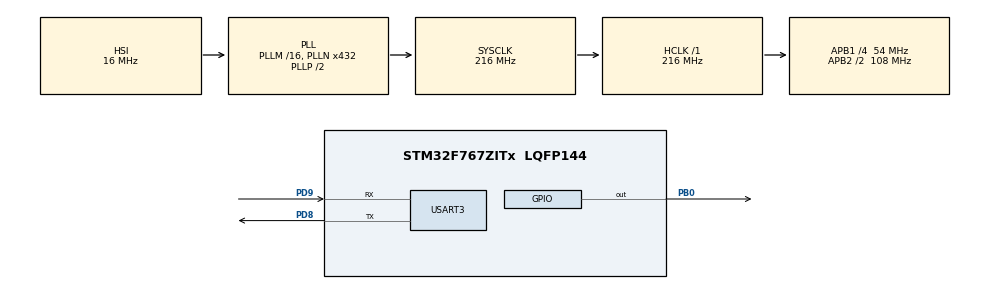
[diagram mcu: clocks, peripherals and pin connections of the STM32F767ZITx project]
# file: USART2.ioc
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Mcu.Family=STM32F7
Mcu.Name=STM32F767ZITx
Mcu.Package=LQFP144
NVIC.PriorityGroup=NVIC_PRIORITYGROUP_4
NVIC.USART3_IRQn=true\:0\:0\:false\:false\:true\:true\:true
PA13.Mode=Serial_Wire
PA13.Signal=SYS_JTMS-SWDIO
PA14.Mode=Serial_Wire
PA14.Signal=SYS_JTCK-SWCLK
PB0.Signal=GPIO_Output
PD8.Mode=Asynchronous
PD8.Signal=USART3_TX
PD9.Mode=Asynchronous
PD9.Signal=USART3_RX
ProjectManager.HeapSize=0x200
ProjectManager.StackSize=0x400
ProjectManager.TargetToolchain=STM32CubeIDE
RCC.AHBFreq_Value=216000000
RCC.APB1CLKDivider=RCC_HCLK_DIV4
RCC.APB1Freq_Value=54000000
RCC.APB1TimFreq_Value=108000000
RCC.APB2CLKDivider=RCC_HCLK_DIV2
RCC.APB2Freq_Value=108000000
RCC.APB2TimFreq_Value=216000000
RCC.CortexFreq_Value=216000000
RCC.HCLKFreq_Value=216000000
RCC.HSE_VALUE=25000000
RCC.HSI_VALUE=16000000
RCC.LSE_VALUE=32768
RCC.PLLN=432
RCC.SYSCLKFreq_VALUE=216000000
RCC.SYSCLKSource=RCC_SYSCLKSOURCE_PLLCLK
RCC.USBFreq_Value=216000000
RCC.VCOOutputFreq_Value=432000000
USART3.VirtualMode-Asynchronous=VM_ASYNC
board=custom

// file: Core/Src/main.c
/* USER CODE BEGIN Header */
/**
  ******************************************************************************
  * @file           : main.c
  * @brief          : Main program body
  ******************************************************************************
  * @attention
  *
  * Copyright (c) 2022 STMicroelectronics.
  * All rights reserved.
  *
  * This software is licensed under terms that can be found in the LICENSE file
  * in the root directory of this software component.
  * If no LICENSE file comes with this software, it is provided AS-IS.
  *
  ******************************************************************************
  */
/* USER CODE END Header */
#include "main.h"

/* USER CODE BEGIN Includes */
#include <stdio.h>
#include <string.h>

/* USER CODE END Includes */

UART_HandleTypeDef huart3;

void SystemClock_Config(void);
static void MX_GPIO_Init(void);
static void MX_USART3_UART_Init(void);

/* USER CODE BEGIN 0 */
char RX_data[5];
char RX_data_buffer[4];
/* USER CODE END 0 */

int main(void)
{

  /* MCU Configuration--------------------------------------------------------*/

  /* Reset of all peripherals, Initializes the Flash interface and the Systick. */
  HAL_Init();

  /* Configure the system clock */
  SystemClock_Config();

  /* Initialize all configured peripherals */
  MX_GPIO_Init();
  MX_USART3_UART_Init();
  HAL_UART_Receive_IT(&huart3, RX_data, 5);
  /* Infinite loop */
  while (1)
  {

  }
}

void SystemClock_Config(void)
{
  RCC_OscInitTypeDef RCC_OscInitStruct = {0};
  RCC_ClkInitTypeDef RCC_ClkInitStruct = {0};

  /** Configure the main internal regulator output voltage
  */
  __HAL_RCC_PWR_CLK_ENABLE();
  __HAL_PWR_VOLTAGESCALING_CONFIG(PWR_REGULATOR_VOLTAGE_SCALE1);
  /** Initializes the RCC Oscillators according to the specified parameters
  * in the RCC_OscInitTypeDef structure.
  */
  RCC_OscInitStruct.OscillatorType = RCC_OSCILLATORTYPE_HSI;
  RCC_OscInitStruct.HSIState = RCC_HSI_ON;
  RCC_OscInitStruct.HSICalibrationValue = RCC_HSICALIBRATION_DEFAULT;
  RCC_OscInitStruct.PLL.PLLState = RCC_PLL_ON;
  RCC_OscInitStruct.PLL.PLLSource = RCC_PLLSOURCE_HSI;
  RCC_OscInitStruct.PLL.PLLM = 16;
  RCC_OscInitStruct.PLL.PLLN = 432;
  RCC_OscInitStruct.PLL.PLLP = RCC_PLLP_DIV2;
  RCC_OscInitStruct.PLL.PLLQ = 2;
  RCC_OscInitStruct.PLL.PLLR = 2;
  if (HAL_RCC_OscConfig(&RCC_OscInitStruct) != HAL_OK)
  {
    Error_Handler();
  }
  /** Activate the Over-Drive mode
  */
  if (HAL_PWREx_EnableOverDrive() != HAL_OK)
  {
    Error_Handler();
  }
  /** Initializes the CPU, AHB and APB buses clocks
  */
  RCC_ClkInitStruct.ClockType = RCC_CLOCKTYPE_HCLK|RCC_CLOCKTYPE_SYSCLK
                              |RCC_CLOCKTYPE_PCLK1|RCC_CLOCKTYPE_PCLK2;
  RCC_ClkInitStruct.SYSCLKSource = RCC_SYSCLKSOURCE_PLLCLK;
  RCC_ClkInitStruct.AHBCLKDivider = RCC_SYSCLK_DIV1;
  RCC_ClkInitStruct.APB1CLKDivider = RCC_HCLK_DIV4;
  RCC_ClkInitStruct.APB2CLKDivider = RCC_HCLK_DIV2;

  if (HAL_RCC_ClockConfig(&RCC_ClkInitStruct, FLASH_LATENCY_7) != HAL_OK)
  {
    Error_Handler();
  }
}

static void MX_USART3_UART_Init(void)
{

  huart3.Instance = USART3;
  huart3.Init.BaudRate = 115200;
  huart3.Init.WordLength = UART_WORDLENGTH_8B;
  huart3.Init.StopBits = UART_STOPBITS_1;
  huart3.Init.Parity = UART_PARITY_NONE;
  huart3.Init.Mode = UART_MODE_TX_RX;
  huart3.Init.HwFlowCtl = UART_HWCONTROL_NONE;
  huart3.Init.OverSampling = UART_OVERSAMPLING_16;
  huart3.Init.OneBitSampling = UART_ONE_BIT_SAMPLE_DISABLE;
  huart3.AdvancedInit.AdvFeatureInit = UART_ADVFEATURE_NO_INIT;
  if (HAL_UART_Init(&huart3) != HAL_OK)
  {
    Error_Handler();
  }

}

static void MX_GPIO_Init(void)
{
  GPIO_InitTypeDef GPIO_InitStruct = {0};

  /* GPIO Ports Clock Enable */
  __HAL_RCC_GPIOB_CLK_ENABLE();
  __HAL_RCC_GPIOD_CLK_ENABLE();
  __HAL_RCC_GPIOA_CLK_ENABLE();

  /*Configure GPIO pin Output Level */
  HAL_GPIO_WritePin(GPIOB, GPIO_PIN_0, GPIO_PIN_RESET);

  /*Configure GPIO pin : PB0 */
  GPIO_InitStruct.Pin = GPIO_PIN_0;
  GPIO_InitStruct.Mode = GPIO_MODE_OUTPUT_PP;
  GPIO_InitStruct.Pull = GPIO_NOPULL;
  GPIO_InitStruct.Speed = GPIO_SPEED_FREQ_LOW;
  HAL_GPIO_Init(GPIOB, &GPIO_InitStruct);

}

/* USER CODE BEGIN 4 */

void HAL_UART_RxCpltCallback(UART_HandleTypeDef *huart){
	if(huart == &huart3){
		if(RX_data[0] == '1'){
			HAL_GPIO_TogglePin(GPIOB, GPIO_PIN_0);

			for(int i = 1; i < strlen(RX_data); i++){
				RX_data_buffer[i - 1] = RX_data[i];
			}
			HAL_UART_Transmit_IT(&huart3, RX_data_buffer, 4);
			HAL_UART_Receive_IT(&huart3, RX_data, 5);
		}
		else if(RX_data[0] == '2'){
			HAL_GPIO_TogglePin(GPIOB, GPIO_PIN_0);

			for(int i = 1; i < strlen(RX_data); i++){
				if(RX_data[i] >= 'a' && RX_data[i] <= 'z'){
					RX_data_buffer[i - 1] = RX_data[i] - 32;
				}
				else{
					RX_data_buffer[i - 1] = RX_data[i];
				}
			}
			HAL_UART_Transmit_IT(&huart3, RX_data_buffer, 4);
			HAL_UART_Receive_IT(&huart3, RX_data, 5);
		}
		else if(RX_data[0] == '3'){
			HAL_GPIO_TogglePin(GPIOB, GPIO_PIN_0);

			for(int i = 1; i < strlen(RX_data); i++){
				if(RX_data[i] >= 'a' && RX_data[i] <= 'z'){
					RX_data_buffer[i - 1] = RX_data[i];
				}
				else{
					RX_data_buffer[i - 1] = RX_data[i] + 32;
				}
			}
			HAL_UART_Transmit_IT(&huart3, RX_data_buffer, 4);
			HAL_UART_Receive_IT(&huart3, RX_data, 5);
		}
	}
}

/* USER CODE END 4 */

void Error_Handler(void)
{
  __disable_irq();
  while (1)
  {
  }
}
